# M05x_registers register map
File version: 0.1
CPU: 
Registers are 32-bit, read-write, reset 0x0 unless marked. A register's access mark holds for its fields unless they carry their own. Offsets are from the block's base; [hi:lo] are bit positions; lines under a group give offsets from that group.

## TMR0 — Registers group
Base 0x40010000
Same registers: TMR1 0x40010020, TMR2 0x40110000, TMR3 0x40110020
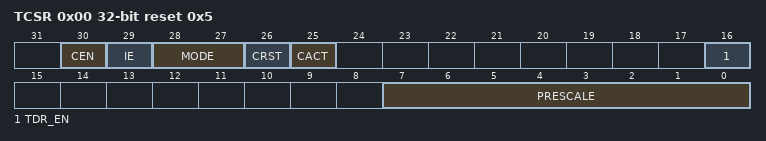
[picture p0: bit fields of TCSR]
0x00 TCSR reset 0x5 (reset mask 0xFFFFFFFA) — Timer0 Control and Status Register
  [30] CEN — Timer Enable Bit 1 = Starts counting 0 = Stops/Suspends counting Note1: In stop status, and then set CEN to 1 will enables the 24-bit up-timer keeps up counting from the last stop counting value. Note2: This bit is auto-cleared by hardware in one-shot mode (MODE[28:27]=00) when the associated timer interrupt is generated (IE[29]=1).
  [29] IE — Interrupt Enable Bit 1 = Enable timer Interrupt. 0 = Disable timer Interrupt. If timer interrupt is enabled, the timer asserts its interrupt signal when the associated up-timer value is equal to TCMPR.
  [28:27] MODE — Timer Operating Mode MODE Timer Operating Mode 00 The timer is operating in the one-shot mode. The associated interrupt signal is generated once (if IE is enabled) and CEN is automatically cleared by hardware. 01 The timer is operating in the periodic mode. The associated interrupt signal is generated periodically (if IE is enabled). 10 The timer is operating in the toggle mode. The interrupt signal is generated periodically (if IE is enabled). And the associated signal (tout) is changing back and forth with 50% duty cycle. 11 Reserved
  [26] CRST — Timer Reset Bit Set this bit will reset the 24-bit up-timer, 8-bit pre-scale counter and also force CEN to 0. 0 = No effect. 1 = Reset Timer's 8-bit pre-scale counter, internal 24-bit up-timer and CEN bit.
  [25] CACT ro — Timer Active Status Bit (Read only) This bit indicates the up-timer status. 0 = Timer is not active. 1 = Timer is active.
  [16] TDR_EN — Data Load Enable When TDR_EN is set, TDR (Timer Data Register) will be updated continuously with the 24-bit up-timer value as the timer is counting. 1 = Timer Data Register update enable. 0 = Timer Data Register update disable.
  [7:0] PRESCALE — Pre-scale Counter Clock input is divided by PRESCALE+1 before it is fed to the counter. If PRESCALE=0, then there is no scaling.
0x04 TCMPR — Timer0 Compare Register
  [23:0] TCMP — Timer Compared Value TCMP is a 24-bit compared register. When the internal 24-bit up-timer counts and its value is equal to TCMP value, a Timer Interrupt is requested if the timer interrupt is enabled with TCSR.IE[29]=1. The TCMP value defines the timer counting cycle time. Time out period = (Period of timer clock input) * (8-bit PRESCALE + 1) * (24-bit TCMP) NOTE1: Never write 0x0 or 0x1 in TCMP, or the core will run into unknown state. NOTE2: No matter CEN is 0 or 1, whenever software write a new value into this register, TIMER will restart counting using this new value and abort previous count.
0x08 TISR — Timer0 Interrupt Status Register
  [0] TIF write-1-clears — Timer Interrupt Flag This bit indicates the interrupt status of Timer. TIF bit is set by hardware when the up counting value of internal 24-bit timer matches the timer compared value (TCMP). It is cleared by writing 1 to this bit.
0x0C TDR ro — Timer0 Data Register
  [23:0] TDR — Timer Data Register When TCSR.TDR_EN is set to 1, the internal 24-bit up-timer value will be loaded into TDR. User can read this register for the up-timer value.

## WDT — Registers group
Base 0x40004000
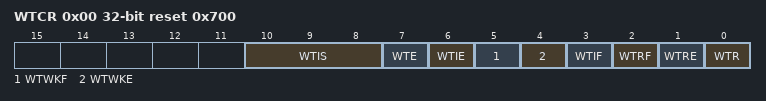
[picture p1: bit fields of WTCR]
0x00 WTCR reset 0x700 (reset mask 0xFFFFF8FF) — Watchdog Timer Control Register
  [10:8] WTIS — Watchdog Timer Interval Select (write protection bit) These three bits select the timeout interval for the Watchdog timer. WTIS Timeout Interval Selection Interrupt Period WTR Timeout Interval (WDT_CLK=12MHz) 000 2^4 * WDT_CLK (2^4 + 1024) * WDT_CLK 1.33 us ~ 86.67 us 001 2^6 * WDT_CLK (2^6 + 1024) * WDT_CLK 5.33 us ~ 90.67 us 010 2^8 * WDT_CLK (2^8 + 1024) * WDT_CLK 21.33 us ~ 106.67 us 011 2^10 * WDT_CLK (2^10 + 1024) * WDT_CLK 85.33 us ~ 170.67 us 100 2^12 * WDT_CLK (2^12 + 1024) * WDT_CLK 341.33 us ~ 426.67 us 101 2^14 * WDT_CLK (2^14 + 1024) * WDT_CLK 1.36 ms ~ 1.45 ms 110 2^16 * WDT_CLK (2^16 + 1024) * WDT_CLK 5.46 ms ~ 5.55 ms 111 2^18 * WDT_CLK (2^18 + 1024) * WDT_CLK 21.84 ms ~ 21.93 ms
  [7] WTE — Watchdog Timer Enable 0= Disable the Watchdog timer (This action will reset the internal counter) 1= Enable the Watchdog timer
  [6] WTIE — Watchdog Timer Interrupt Enable 0= Disable the Watchdog timer interrupt 1= Enable the Watchdog timer interrupt
  [5] WTWKF write-1-clears — Watchdog Timer Wakeup Flag If Watchdog timer causes CPU wakes up from power-down mode, this bit will be set to high. It must be cleared by software with a write 1 to this bit. 1 = CPU wake up from sleep or power-down mode by Watchdog timeout. 0 = Watchdog timer does not cause CPU wakeup. NOTE: Write 1 to clear this bit to zero.
  [4] WTWKE — Watchdog Timer Wakeup Function Enable bit 0 = Disable Watchdog timer Wakeup CPU function. 1 = Enable the Wakeup function that Watchdog timer timeout can wake up CPU from power-down mode.
  [3] WTIF write-1-clears — Watchdog Timer Interrupt Flag If the Watchdog timer interrupt is enabled, then the hardware will set this bit to indicate that the Watchdog timer interrupt has occurred. If the Watchdog timer interrupt is not enabled, then this bit indicates that a timeout period has elapsed. 0= Watchdog timer interrupt does not occur 1= Watchdog timer interrupt occurs NOTE: Write 1 to clear this bit to zero.
  [2] WTRF write-1-clears — Watchdog Timer Reset Flag When the Watchdog timer initiates a reset, the hardware will set this bit. This flag can be read by software to determine the source of reset. Software is responsible to clear it manually by writing 1 to it. If WTRE is disabled, then the Watchdog timer has no effect on this bit. 0= Watchdog timer reset does not occur 1= Watchdog timer reset occurs NOTE: This bit is cleared by writing 1 to this bit.
  [1] WTRE — Watchdog Timer Reset Enable Setting this bit will enable the Watchdog timer reset function. 0= Disable Watchdog timer reset function 1= Enable Watchdog timer reset function
  [0] WTR — Clear Watchdog Timer Set this bit will clear the Watchdog timer. 0= Writing 0 to this bit has no effect 1= Reset the contents of the Watchdog timer NOTE: This bit will auto clear after few clock cycle
